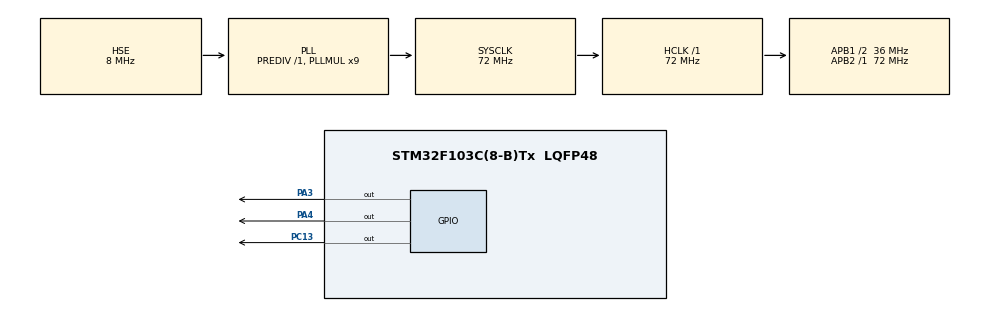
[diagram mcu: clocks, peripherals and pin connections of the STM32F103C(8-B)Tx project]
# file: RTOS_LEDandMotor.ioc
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FREERTOS.Tasks01=LED_100ms,2,128,StartTaskLED,Default,NULL,Dynamic,NULL,NULL;moveMotor,2,128,StartTaskMotor,Default,NULL,Dynamic,NULL,NULL
Mcu.Family=STM32F1
Mcu.Name=STM32F103C(8-B)Tx
Mcu.Package=LQFP48
NVIC.PriorityGroup=NVIC_PRIORITYGROUP_4
PA13.Mode=Serial_Wire
PA13.Signal=SYS_JTMS-SWDIO
PA14.Mode=Serial_Wire
PA14.Signal=SYS_JTCK-SWCLK
PA3.Signal=GPIO_Output
PA4.Signal=GPIO_Output
PC13-TAMPER-RTC.Signal=GPIO_Output
PD0-OSC_IN.Mode=HSE-External-Oscillator
PD0-OSC_IN.Signal=RCC_OSC_IN
PD1-OSC_OUT.Mode=HSE-External-Oscillator
PD1-OSC_OUT.Signal=RCC_OSC_OUT
ProjectManager.HeapSize=0x200
ProjectManager.StackSize=0x400
ProjectManager.TargetToolchain=MDK-ARM V5.32
RCC.AHBFreq_Value=72000000
RCC.APB1CLKDivider=RCC_HCLK_DIV2
RCC.APB1Freq_Value=36000000
RCC.APB1TimFreq_Value=72000000
RCC.APB2Freq_Value=72000000
RCC.APB2TimFreq_Value=72000000
RCC.HCLKFreq_Value=72000000
RCC.PLLMUL=RCC_PLL_MUL9
RCC.PLLSourceVirtual=RCC_PLLSOURCE_HSE
RCC.SYSCLKFreq_VALUE=72000000
RCC.SYSCLKSource=RCC_SYSCLKSOURCE_PLLCLK
RCC.USBFreq_Value=72000000
VP_FREERTOS_VS_CMSIS_V1.Mode=CMSIS_V1
board=custom

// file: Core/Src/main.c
/* USER CODE BEGIN Header */
/**
  ******************************************************************************
  * @file           : main.c
  * @brief          : Main program body
  ******************************************************************************
  * @attention
  *
  * Copyright (c) 2025 STMicroelectronics.
  * All rights reserved.
  *
  * This software is licensed under terms that can be found in the LICENSE file
  * in the root directory of this software component.
  * If no LICENSE file comes with this software, it is provided AS-IS.
  *
  ******************************************************************************
  */
/* USER CODE END Header */
#include "main.h"
#include "cmsis_os.h"
#include "gpio.h"

void SystemClock_Config(void);
void MX_FREERTOS_Init(void);

int main(void)
{

  /* MCU Configuration--------------------------------------------------------*/

  /* Reset of all peripherals, Initializes the Flash interface and the Systick. */
  HAL_Init();

  /* Configure the system clock */
  SystemClock_Config();

  /* Initialize all configured peripherals */
  MX_GPIO_Init();

  /* Call init function for freertos objects (in cmsis_os2.c) */
  MX_FREERTOS_Init();

  /* Start scheduler */
  osKernelStart();

  /* We should never get here as control is now taken by the scheduler */

  /* Infinite loop */
  while (1)
  {

  }
}

void SystemClock_Config(void)
{
  RCC_OscInitTypeDef RCC_OscInitStruct = {0};
  RCC_ClkInitTypeDef RCC_ClkInitStruct = {0};

  /** Initializes the RCC Oscillators according to the specified parameters
  * in the RCC_OscInitTypeDef structure.
  */
  RCC_OscInitStruct.OscillatorType = RCC_OSCILLATORTYPE_HSE;
  RCC_OscInitStruct.HSEState = RCC_HSE_ON;
  RCC_OscInitStruct.HSEPredivValue = RCC_HSE_PREDIV_DIV1;
  RCC_OscInitStruct.HSIState = RCC_HSI_ON;
  RCC_OscInitStruct.PLL.PLLState = RCC_PLL_ON;
  RCC_OscInitStruct.PLL.PLLSource = RCC_PLLSOURCE_HSE;
  RCC_OscInitStruct.PLL.PLLMUL = RCC_PLL_MUL9;
  if (HAL_RCC_OscConfig(&RCC_OscInitStruct) != HAL_OK)
  {
    Error_Handler();
  }

  /** Initializes the CPU, AHB and APB buses clocks
  */
  RCC_ClkInitStruct.ClockType = RCC_CLOCKTYPE_HCLK|RCC_CLOCKTYPE_SYSCLK
                              |RCC_CLOCKTYPE_PCLK1|RCC_CLOCKTYPE_PCLK2;
  RCC_ClkInitStruct.SYSCLKSource = RCC_SYSCLKSOURCE_PLLCLK;
  RCC_ClkInitStruct.AHBCLKDivider = RCC_SYSCLK_DIV1;
  RCC_ClkInitStruct.APB1CLKDivider = RCC_HCLK_DIV2;
  RCC_ClkInitStruct.APB2CLKDivider = RCC_HCLK_DIV1;

  if (HAL_RCC_ClockConfig(&RCC_ClkInitStruct, FLASH_LATENCY_2) != HAL_OK)
  {
    Error_Handler();
  }
}

void Error_Handler(void)
{
  __disable_irq();
  while (1)
  {
  }
}

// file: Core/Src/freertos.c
/* USER CODE BEGIN Header */
/**
  ******************************************************************************
  * File Name          : freertos.c
  * Description        : Code for freertos applications
  ******************************************************************************
  * @attention
  *
  * Copyright (c) 2025 STMicroelectronics.
  * All rights reserved.
  *
  * This software is licensed under terms that can be found in the LICENSE file
  * in the root directory of this software component.
  * If no LICENSE file comes with this software, it is provided AS-IS.
  *
  ******************************************************************************
  */
/* USER CODE END Header */

#include "FreeRTOS.h"
#include "task.h"
#include "main.h"
#include "cmsis_os.h"

osThreadId LED_100msHandle;
osThreadId moveMotorHandle;

void StartTaskLED(void const * argument);
void StartTaskMotor(void const * argument);

void MX_FREERTOS_Init(void); /* (MISRA C 2004 rule 8.1) */

/* GetIdleTaskMemory prototype (linked to static allocation support) */
void vApplicationGetIdleTaskMemory( StaticTask_t **ppxIdleTaskTCBBuffer, StackType_t **ppxIdleTaskStackBuffer, uint32_t *pulIdleTaskStackSize );

/* USER CODE BEGIN GET_IDLE_TASK_MEMORY */
static StaticTask_t xIdleTaskTCBBuffer;
static StackType_t xIdleStack[configMINIMAL_STACK_SIZE];

void vApplicationGetIdleTaskMemory( StaticTask_t **ppxIdleTaskTCBBuffer, StackType_t **ppxIdleTaskStackBuffer, uint32_t *pulIdleTaskStackSize )
{
  *ppxIdleTaskTCBBuffer = &xIdleTaskTCBBuffer;
  *ppxIdleTaskStackBuffer = &xIdleStack[0];
  *pulIdleTaskStackSize = configMINIMAL_STACK_SIZE;
  /* place for user code */
}
/* USER CODE END GET_IDLE_TASK_MEMORY */

void MX_FREERTOS_Init(void) {

  /* Create the thread(s) */
  /* definition and creation of LED_100ms */
  osThreadDef(LED_100ms, StartTaskLED, osPriorityHigh, 0, 128);
  LED_100msHandle = osThreadCreate(osThread(LED_100ms), NULL);

  /* definition and creation of moveMotor */
  osThreadDef(moveMotor, StartTaskMotor, osPriorityHigh, 0, 128);
  moveMotorHandle = osThreadCreate(osThread(moveMotor), NULL);

}

void StartTaskLED(void const * argument)
{
  /* USER CODE BEGIN StartTaskLED */
  /* Infinite loop */
  for(;;)
  {
		HAL_GPIO_WritePin(GPIOC ,GPIO_PIN_13,0);
		osDelay(100);
		HAL_GPIO_WritePin(GPIOC ,GPIO_PIN_13,1);
		osDelay(100);
    osDelay(1);
  }
  /* USER CODE END StartTaskLED */
}

void StartTaskMotor(void const * argument)
{
  /* USER CODE BEGIN StartTaskMotor */
  /* Infinite loop */
  for(;;)
  {
		HAL_GPIO_WritePin(GPIOA ,GPIO_PIN_3,0);
		HAL_GPIO_WritePin(GPIOA ,GPIO_PIN_4,1);
    osDelay(1);
  }
  /* USER CODE END StartTaskMotor */
}
